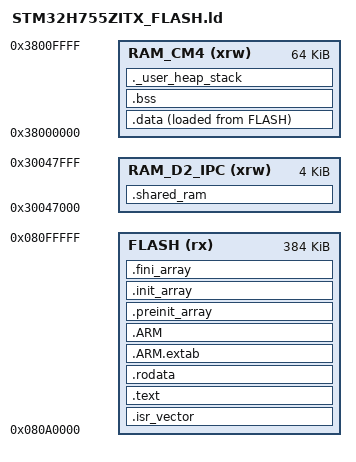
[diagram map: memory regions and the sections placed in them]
/*
******************************************************************************
**
**  File        : LinkerScript.ld
**
**  Author      : STM32CubeIDE
**
**  Abstract    : Linker script for STM32H7 series
**                1024Kbytes FLASH and 288Kbytes RAM
**
**                Set heap size, stack size and stack location according
**                to application requirements.
**
**                Set memory bank area and size if external memory is used.
**
**  Target      : STMicroelectronics STM32
**
**  Distribution: The file is distributed as is, without any warranty
**                of any kind.
**
*****************************************************************************
** @attention
**
** Copyright (c) 2025 STMicroelectronics.
** All rights reserved.
**
** This software is licensed under terms that can be found in the LICENSE file
** in the root directory of this software component.
** If no LICENSE file comes with this software, it is provided AS-IS.
**
****************************************************************************
*/

/* Entry Point */
ENTRY(Reset_Handler)

/* Highest address of the user mode stack */
_estack = ORIGIN(RAM_CM4) + LENGTH(RAM_CM4); /* end of RAM */
/* Generate a link error if heap and stack don't fit into RAM */
_Min_Heap_Size = 0x200;      /* required amount of heap  */
_Min_Stack_Size = 0x400; /* required amount of stack */

/* Specify the memory areas */
MEMORY
{
	FLASH (rx)     : ORIGIN = 0x080A0000, LENGTH = 384K
	/**CM4_start = D2_end - IPC_size - CM4_size : D2 End: 0x3000_0000 + 0x48000(288 KB) = 0x3004_8000
	IPC: 0x3004_8000 - 0x4000(16k) = 0x3004_4000
	CM4 start = 0x3004_4000 - 0x8000 = 0x3003_C000 (CM4 origin)
	*/
  /* CM4 private RAM in D2 (DO NOT use 0x10000000, DO NOT use 0x20000000) */
  /*RAM_CM4 (xrw)    : ORIGIN = 0x3003C000, LENGTH = 32K*/

  /* Shared IPC window (must match CM7 exactly) */
  RAM_CM4 (xrw)   : ORIGIN = 0x38000000, LENGTH = 64K /**This is RAM_D3, renamed it here*/
  RAM_D2_IPC (xrw) : ORIGIN = 0x30047000, LENGTH = 4K

}

/* Define output sections */
SECTIONS
{
  /* The startup code goes first into FLASH */
  .isr_vector :
  {
    . = ALIGN(4);
    KEEP(*(.isr_vector)) /* Startup code */
    . = ALIGN(4);
  } >FLASH

  /* The program code and other data goes into FLASH */
  .text :
  {
    . = ALIGN(4);
    *(.text)           /* .text sections (code) */
    *(.text*)          /* .text* sections (code) */
    *(.glue_7)         /* glue arm to thumb code */
    *(.glue_7t)        /* glue thumb to arm code */
    *(.eh_frame)

    KEEP (*(.init))
    KEEP (*(.fini))

    . = ALIGN(4);
    _etext = .;        /* define a global symbols at end of code */
  } >FLASH

  /* Constant data goes into FLASH */
  .rodata :
  {
    . = ALIGN(4);
    *(.rodata)         /* .rodata sections (constants, strings, etc.) */
    *(.rodata*)        /* .rodata* sections (constants, strings, etc.) */
    . = ALIGN(4);
  } >FLASH

  .ARM.extab (READONLY) : /* The READONLY keyword is only supported in GCC11 and later, remove it if using GCC10 or earlier. */
  {
    *(.ARM.extab* .gnu.linkonce.armextab.*)
  } >FLASH
  .ARM (READONLY) : /* The READONLY keyword is only supported in GCC11 and later, remove it if using GCC10 or earlier. */
  {
    __exidx_start = .;
    *(.ARM.exidx*)
    __exidx_end = .;
  } >FLASH

  .preinit_array (READONLY) : /* The READONLY keyword is only supported in GCC11 and later, remove it if using GCC10 or earlier. */
  {
    PROVIDE_HIDDEN (__preinit_array_start = .);
    KEEP (*(.preinit_array*))
    PROVIDE_HIDDEN (__preinit_array_end = .);
  } >FLASH
  .init_array (READONLY) : /* The READONLY keyword is only supported in GCC11 and later, remove it if using GCC10 or earlier. */
  {
    PROVIDE_HIDDEN (__init_array_start = .);
    KEEP (*(SORT(.init_array.*)))
    KEEP (*(.init_array*))
    PROVIDE_HIDDEN (__init_array_end = .);
  } >FLASH
  .fini_array (READONLY) : /* The READONLY keyword is only supported in GCC11 and later, remove it if using GCC10 or earlier. */
  {
    PROVIDE_HIDDEN (__fini_array_start = .);
    KEEP (*(SORT(.fini_array.*)))
    KEEP (*(.fini_array*))
    PROVIDE_HIDDEN (__fini_array_end = .);
  } >FLASH

  /* used by the startup to initialize data */
  _sidata = LOADADDR(.data);

  /* Initialized data sections goes into RAM, load LMA copy after code */
  .data :
  {
    . = ALIGN(4);
    _sdata = .;        /* create a global symbol at data start */
    *(.data)           /* .data sections */
    *(.data*)          /* .data* sections */
    *(.RamFunc)        /* .RamFunc sections */
    *(.RamFunc*)       /* .RamFunc* sections */

    . = ALIGN(4);
    _edata = .;        /* define a global symbol at data end */
  } >RAM_CM4 AT> FLASH

  /* Uninitialized data section */
  . = ALIGN(4);
  .bss :
  {
    /* This is used by the startup in order to initialize the .bss section */
    _sbss = .;         /* define a global symbol at bss start */
    __bss_start__ = _sbss;
    *(.bss)
    *(.bss*)
    *(COMMON)

    . = ALIGN(4);
    _ebss = .;         /* define a global symbol at bss end */
    __bss_end__ = _ebss;
  } >RAM_CM4

  /* User_heap_stack section, used to check that there is enough RAM left */
  ._user_heap_stack :
  {
    . = ALIGN(8);
    PROVIDE ( end = . );
    PROVIDE ( _end = . );
    . = . + _Min_Heap_Size;
    . = . + _Min_Stack_Size;
    . = ALIGN(8);
  } >RAM_CM4

	/* CM7 <-> CM4 shared memory */
	.shared_ram (NOLOAD) :
	{
	    . = ALIGN(32);
	    *(.shared_ram)
	    . = ALIGN(32);
	} > RAM_D2_IPC

  /* Remove information from the standard libraries */
  /DISCARD/ :
  {
    libc.a ( * )
    libm.a ( * )
    libgcc.a ( * )
  }

  .ARM.attributes 0 : { *(.ARM.attributes) }
}

/* ---- IPC safety checks (CM4) ---- */

/* 1) Shared section must fit in IPC window */
ASSERT(SIZEOF(.shared_ram) <= LENGTH(RAM_D2_IPC),
       "ERROR: .shared_ram larger than RAM_D2_IPC region");

/* 2) Guard: RAM_D2_IPC window sanity (optional but useful) */
ASSERT(ORIGIN(RAM_D2_IPC) >= 0x30000000 && (ORIGIN(RAM_D2_IPC) + LENGTH(RAM_D2_IPC)) <= 0x30048000,
       "ERROR: RAM_D2_IPC is outside STM32H7 D2 SRAM range");

/* 3) CM4 must NOT be linked into D2 (except shared) — ensures your RAM_D3 exists & is used */
ASSERT(LENGTH(RAM_CM4) > 0,
       "ERROR: RAM_CM4 not defined or zero length");
